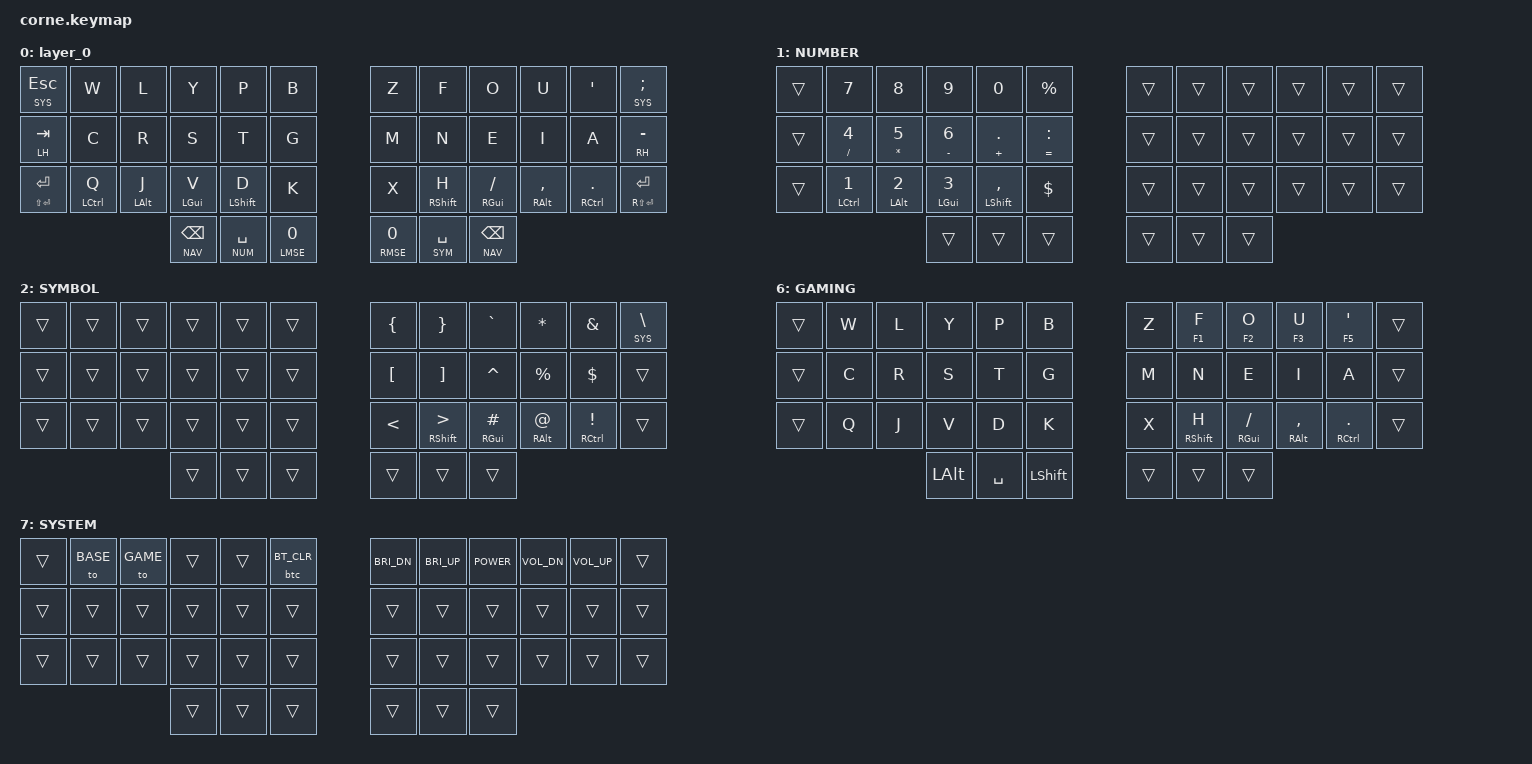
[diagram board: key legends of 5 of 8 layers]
 /*
 * Copyright (c) 2020 The ZMK Contributors
 *
 * SPDX-License-Identifier: MIT
 */

// System files
#include <behaviors.dtsi>
#include <dt-bindings/zmk/keys.h>
#include <dt-bindings/zmk/bt.h>

// Custom files
#include "c-matrix.dtsi"
#include "c-behaviors.dtsi"
#include "c-macros.dtsi"
#include "c-combos.dtsi"
#include "c-mouse.dtsi"

/ {
    keymap {
        compatible = "zmk,keymap";
        layer_0 {
            // display-name = "BASE";
            bindings = <
            //╭────────────────────────┬────────────────────────┬────────────────────────┬────────────────────────┬────────────────────────┬────────────────────────╮  ╭────────────────────────┬────────────────────────┬────────────────────────┬────────────────────────┬────────────────────────┬────────────────────────╮
                &lt SYS ESC              &kp W                    &kp L                    &kp Y                    &kp P                    &kp B                       &kp Z                    &kp F                    &kp O                    &kp U                    &kp SQT                  &lt SYS SEMI
            //├────────────────────────┼────────────────────────┼────────────────────────┼────────────────────────┼────────────────────────┼────────────────────────┤  ├────────────────────────┼────────────────────────┼────────────────────────┼────────────────────────┼────────────────────────┼────────────────────────┤
                &ht LH TAB               &kp C                    &kp R                    &kp S                    &kp T                    &kp G                       &kp M                    &kp N                    &kp E                    &kp I                    &kp A                    &ht RH MINUS
            //├────────────────────────┼────────────────────────┼────────────────────────┼────────────────────────┼────────────────────────┼────────────────────────┤  ├────────────────────────┼────────────────────────┼────────────────────────┼────────────────────────┼────────────────────────┼────────────────────────┤
                &ht LS(RET) RET          &hml LCTRL Q             &hml LALT J              &hml LGUI V              &hmls LSHFT D            &kp K                       &kp X                    &hmrs RSHFT H            &hmr RGUI FSLH           &hmr RALT COMMA          &hmr RCTRL DOT           &ht RS(RET) RET
            //╰────────────────────────┴────────────────────────┴────────────────────────┼────────────────────────┼────────────────────────┼────────────────────────┤  ├────────────────────────┼────────────────────────┼────────────────────────┼────────────────────────┴────────────────────────┴────────────────────────╯
                                                                                           &lt NAV BSPC             &lt NUM SPACE            &ltr LMSE 0                 &ltr RMSE 0              &lt SYM SPACE            &lt NAV BSPC
            //                                                                           ╰────────────────────────┴────────────────────────┴────────────────────────╯  ╰────────────────────────┴────────────────────────┴────────────────────────╯
            >;
        };
        layer_1 {
            display-name = "NUMBER";
            bindings = <
            //╭────────────────────────┬────────────────────────┬────────────────────────┬────────────────────────┬────────────────────────┬────────────────────────╮  ╭────────────────────────┬────────────────────────┬────────────────────────┬────────────────────────┬────────────────────────┬────────────────────────╮
                &trans                   &kp N7                   &kp N8                   &kp N9                   &kp N0                   &kp PRCNT                   &trans                   &trans                   &trans                   &trans                   &trans                   &trans
            //├────────────────────────┼────────────────────────┼────────────────────────┼────────────────────────┼────────────────────────┼────────────────────────┤  ├────────────────────────┼────────────────────────┼────────────────────────┼────────────────────────┼────────────────────────┼────────────────────────┤
                &trans                   &ht FSLH N4              &ht ASTRK N5             &ht MINUS N6             &ht PLUS DOT             &ht EQUAL COLON             &trans                   &trans                   &trans                   &trans                   &trans                   &trans
            //├────────────────────────┼────────────────────────┼────────────────────────┼────────────────────────┼────────────────────────┼────────────────────────┤  ├────────────────────────┼────────────────────────┼────────────────────────┼────────────────────────┼────────────────────────┼────────────────────────┤
                &trans                   &ht LCTRL N1             &ht LALT N2              &ht LGUI N3              &ht LSHFT COMMA          &kp DLLR                    &trans                   &trans                   &trans                   &trans                   &trans                   &trans
            //╰────────────────────────┴────────────────────────┴────────────────────────┼────────────────────────┼────────────────────────┼────────────────────────┤  ├────────────────────────┼────────────────────────┼────────────────────────┼────────────────────────┴────────────────────────┴────────────────────────╯
                                                                                           &trans                   &trans                   &trans                      &trans                   &trans                   &trans
            //                                                                           ╰────────────────────────┴────────────────────────┴────────────────────────╯  ╰────────────────────────┴────────────────────────┴────────────────────────╯
            >;
        };
        layer_2 {
            display-name = "SYMBOL";
            bindings = <
            //╭────────────────────────┬────────────────────────┬────────────────────────┬────────────────────────┬────────────────────────┬────────────────────────╮  ╭────────────────────────┬────────────────────────┬────────────────────────┬────────────────────────┬────────────────────────┬────────────────────────╮
                &trans                   &trans                   &trans                   &trans                   &trans                   &trans                      &kp LBRC                 &kp RBRC                 &kp GRAVE                &kp ASTRK                &kp AMPS                 &lt SYS BSLH
            //├────────────────────────┼────────────────────────┼────────────────────────┼────────────────────────┼────────────────────────┼────────────────────────┤  ├────────────────────────┼────────────────────────┼────────────────────────┼────────────────────────┼────────────────────────┼────────────────────────┤
                &trans                   &trans                   &trans                   &trans                   &trans                   &trans                      &kp LBKT                 &kp RBKT                 &kp CARET                &kp PRCNT                &kp DLLR                 &trans
            //├────────────────────────┼────────────────────────┼────────────────────────┼────────────────────────┼────────────────────────┼────────────────────────┤  ├────────────────────────┼────────────────────────┼────────────────────────┼────────────────────────┼────────────────────────┼────────────────────────┤
                &trans                   &trans                   &trans                   &trans                   &trans                   &trans                      &kp LT                   &ht RSHFT GT             &ht RGUI HASH            &ht RALT AT              &ht RCTRL EXCL           &trans
            //╰────────────────────────┴────────────────────────┴────────────────────────┼────────────────────────┼────────────────────────┼────────────────────────┤  ├────────────────────────┼────────────────────────┼────────────────────────┼────────────────────────┴────────────────────────┴────────────────────────╯
                                                                                           &trans                   &trans                   &trans                      &trans                   &trans                   &trans
            //                                                                           ╰────────────────────────┴────────────────────────┴────────────────────────╯  ╰────────────────────────┴────────────────────────┴────────────────────────╯
            >;
        };
        layer_3 {
            display-name = "LMSE";
            bindings = <
            //╭────────────────────────┬────────────────────────┬────────────────────────┬────────────────────────┬────────────────────────┬────────────────────────╮  ╭────────────────────────┬────────────────────────┬────────────────────────┬────────────────────────┬────────────────────────┬────────────────────────╮
                &trans                   &ht LSG(Z) LG(Z)         &ht LSG(X) LG(X)         &ht LSG(C) LG(C)         &ht LSG(V) LG(V)         &ht LS(A) LG(A)             &ht RAG(ESC) RG(Q)       &ht RSG(W) RG(W)         &ht RSG(T) RG(T)         &ht RSG(R) RG(R)         &kp RC(RG(F))            &trans
            //├────────────────────────┼────────────────────────┼────────────────────────┼────────────────────────┼────────────────────────┼────────────────────────┤  ├────────────────────────┼────────────────────────┼────────────────────────┼────────────────────────┼────────────────────────┼────────────────────────┤
                &trans                   MML                      MMD                      MMU                      MMR                      &trans                      &trans                   MSR                      MSU                      MSD                      MSL                      &trans
            //├────────────────────────┼────────────────────────┼────────────────────────┼────────────────────────┼────────────────────────┼────────────────────────┤  ├────────────────────────┼────────────────────────┼────────────────────────┼────────────────────────┼────────────────────────┼────────────────────────┤
                &trans                   &ht LCTRL LSC(TAB)       &ht LALT LG(LBKT)        &ht LGUI LG(RBKT)        &ht LSHFT LC(TAB)        &trans                      &trans                   &ht RSHFT RC(LEFT)       &ht RGUI RC(DOWN)        &ht RALT RC(UP)          &ht RCTRL RC(RIGHT)      &trans
            //╰────────────────────────┴────────────────────────┴────────────────────────┼────────────────────────┼────────────────────────┼────────────────────────┤  ├────────────────────────┼────────────────────────┼────────────────────────┼────────────────────────┴────────────────────────┴────────────────────────╯
                                                                                           &trans                   &trans                   &trans                      &lt RMSE LSG(N9)         &mkp LCLK                &mlt NAV RCLK
            //                                                                           ╰────────────────────────┴────────────────────────┴────────────────────────╯  ╰────────────────────────┴────────────────────────┴────────────────────────╯
            >;
        };
        layer_4 {
            display-name = "RMSE";
            bindings = <
            //╭────────────────────────┬────────────────────────┬────────────────────────┬────────────────────────┬────────────────────────┬────────────────────────╮  ╭────────────────────────┬────────────────────────┬────────────────────────┬────────────────────────┬────────────────────────┬────────────────────────╮
                &trans                   &ht LSG(Z) LG(Z)         &ht LSG(X) LG(X)         &ht LSG(C) LG(C)         &ht LSG(V) LG(V)         &ht LS(A) LG(A)             &ht RAG(ESC) RG(Q)       &ht RSG(W) RG(W)         &ht RSG(T) RG(T)         &ht RSG(R) RG(R)         &kp RC(RG(F))            &trans
            //├────────────────────────┼────────────────────────┼────────────────────────┼────────────────────────┼────────────────────────┼────────────────────────┤  ├────────────────────────┼────────────────────────┼────────────────────────┼────────────────────────┼────────────────────────┼────────────────────────┤
                &trans                   MML                      MMD                      MMU                      MMR                      &trans                      &trans                   MSR                      MSU                      MSD                      MSL                      &trans
            //├────────────────────────┼────────────────────────┼────────────────────────┼────────────────────────┼────────────────────────┼────────────────────────┤  ├────────────────────────┼────────────────────────┼────────────────────────┼────────────────────────┼────────────────────────┼────────────────────────┤
                &trans                   &ht LCTRL LSC(TAB)       &ht LALT LG(LBKT)        &ht LGUI LG(RBKT)        &ht LSHFT LC(TAB)        &trans                      &trans                   &ht RSHFT RC(LEFT)       &ht RGUI RC(DOWN)        &ht RALT RC(UP)          &ht RCTRL RC(RIGHT)      &trans
            //╰────────────────────────┴────────────────────────┴────────────────────────┼────────────────────────┼────────────────────────┼────────────────────────┤  ├────────────────────────┼────────────────────────┼────────────────────────┼────────────────────────┴────────────────────────┴────────────────────────╯
                                                                                           &mlt NAV RCLK            &mkp LCLK                &lt LMSE LSG(N9)            &trans                   &trans                   &trans
            //                                                                           ╰────────────────────────┴────────────────────────┴────────────────────────╯  ╰────────────────────────┴────────────────────────┴────────────────────────╯
            >;
        };
        layer_5 {
            display-name = "NAV";
            bindings = <
            //╭────────────────────────┬────────────────────────┬────────────────────────┬────────────────────────┬────────────────────────┬────────────────────────╮  ╭────────────────────────┬────────────────────────┬────────────────────────┬────────────────────────┬────────────────────────┬────────────────────────╮
                &trans                   &ht LSG(Z) LG(Z)         &ht LSG(X) LG(X)         &ht LSG(C) LG(C)         &ht LSG(V) LG(V)         &ht LS(A) LG(A)             &ht RAG(ESC) RG(Q)       &ht RSG(W) RG(W)         &ht RSG(T) RG(T)         &ht RSG(R) RG(R)         &kp RC(RG(F))            &trans
            //├────────────────────────┼────────────────────────┼────────────────────────┼────────────────────────┼────────────────────────┼────────────────────────┤  ├────────────────────────┼────────────────────────┼────────────────────────┼────────────────────────┼────────────────────────┼────────────────────────┤
                &trans                   &kp LEFT                 &kp DOWN                 &kp UP                   &kp RIGHT                &trans                      &trans                   &kp LEFT                 &kp DOWN                 &kp UP                   &kp RIGHT                &trans
            //├────────────────────────┼────────────────────────┼────────────────────────┼────────────────────────┼────────────────────────┼────────────────────────┤  ├────────────────────────┼────────────────────────┼────────────────────────┼────────────────────────┼────────────────────────┼────────────────────────┤
                &trans                   &ht LCTRL LSG(LEFT)      &ht LALT LSA(LEFT)       &ht LGUI LSA(RIGHT)      &ht LSHFT LSG(RIGHT)     &trans                      &trans                   &ht RSHFT RG(LEFT)       &ht RGUI RA(LEFT)        &ht RALT RA(RIGHT)       &ht RCTRL RG(RIGHT)      &trans
            //╰────────────────────────┴────────────────────────┴────────────────────────┼────────────────────────┼────────────────────────┼────────────────────────┤  ├────────────────────────┼────────────────────────┼────────────────────────┼────────────────────────┴────────────────────────┴────────────────────────╯
                                                                                           &trans                   &trans                   &trans                      &trans                   &trans                   &trans
            //                                                                           ╰────────────────────────┴────────────────────────┴────────────────────────╯  ╰────────────────────────┴────────────────────────┴────────────────────────╯
            >;
        };
        layer_6 {
            display-name = "GAMING";
            bindings = <
            //╭────────────────────────┬────────────────────────┬────────────────────────┬────────────────────────┬────────────────────────┬────────────────────────╮  ╭────────────────────────┬────────────────────────┬────────────────────────┬────────────────────────┬────────────────────────┬────────────────────────╮
                &trans                   &kp W                    &kp L                    &kp Y                    &kp P                    &kp B                       &kp Z                    &ht F1 F                 &ht F2 O                 &ht F3 U                 &ht F5 SQT               &trans
            //├────────────────────────┼────────────────────────┼────────────────────────┼────────────────────────┼────────────────────────┼────────────────────────┤  ├────────────────────────┼────────────────────────┼────────────────────────┼────────────────────────┼────────────────────────┼────────────────────────┤
                &trans                   &kp C                    &kp R                    &kp S                    &kp T                    &kp G                       &kp M                    &kp N                    &kp E                    &kp I                    &kp A                    &trans
            //├────────────────────────┼────────────────────────┼────────────────────────┼────────────────────────┼────────────────────────┼────────────────────────┤  ├────────────────────────┼────────────────────────┼────────────────────────┼────────────────────────┼────────────────────────┼────────────────────────┤
                &trans                   &kp Q                    &kp J                    &kp V                    &kp D                    &kp K                       &kp X                    &hmr RSHFT H             &hmr RGUI FSLH           &hmr RALT COMMA          &hmr RCTRL DOT           &trans
            //╰────────────────────────┴────────────────────────┴────────────────────────┼────────────────────────┼────────────────────────┼────────────────────────┤  ├────────────────────────┼────────────────────────┼────────────────────────┼────────────────────────┴────────────────────────┴────────────────────────╯
                                                                                           &kp LALT                 &kp SPACE                &kp LSHFT                   &trans                   &trans                   &trans
            //                                                                           ╰────────────────────────┴────────────────────────┴────────────────────────╯  ╰────────────────────────┴────────────────────────┴────────────────────────╯
            >;
        };
        layer_7 {
            display-name = "SYSTEM";
            bindings = <
            //╭────────────────────────┬────────────────────────┬────────────────────────┬────────────────────────┬────────────────────────┬────────────────────────╮  ╭────────────────────────┬────────────────────────┬────────────────────────┬────────────────────────┬────────────────────────┬────────────────────────╮
                &trans                   &to BASE                 &to GAME                 &trans                   &trans                   &btc BT_CLR                 &kp C_BRI_DN             &kp C_BRI_UP             &kp C_POWER              &kp C_VOL_DN             &kp C_VOL_UP             &trans
            //├────────────────────────┼────────────────────────┼────────────────────────┼────────────────────────┼────────────────────────┼────────────────────────┤  ├────────────────────────┼────────────────────────┼────────────────────────┼────────────────────────┼────────────────────────┼────────────────────────┤
                &trans                   &trans                   &trans                   &trans                   &trans                   &trans                      &trans                   &trans                   &trans                   &trans                   &trans                   &trans
            //├────────────────────────┼────────────────────────┼────────────────────────┼────────────────────────┼────────────────────────┼────────────────────────┤  ├────────────────────────┼────────────────────────┼────────────────────────┼────────────────────────┼────────────────────────┼────────────────────────┤
                &trans                   &trans                   &trans                   &trans                   &trans                   &trans                      &trans                   &trans                   &trans                   &trans                   &trans                   &trans
            //╰────────────────────────┴────────────────────────┴────────────────────────┼────────────────────────┼────────────────────────┼────────────────────────┤  ├────────────────────────┼────────────────────────┼────────────────────────┼────────────────────────┴────────────────────────┴────────────────────────╯
                                                                                           &trans                   &trans                   &trans                      &trans                   &trans                   &trans
            //                                                                           ╰────────────────────────┴────────────────────────┴────────────────────────╯  ╰────────────────────────┴────────────────────────┴────────────────────────╯
            >;
        };
    };
};
